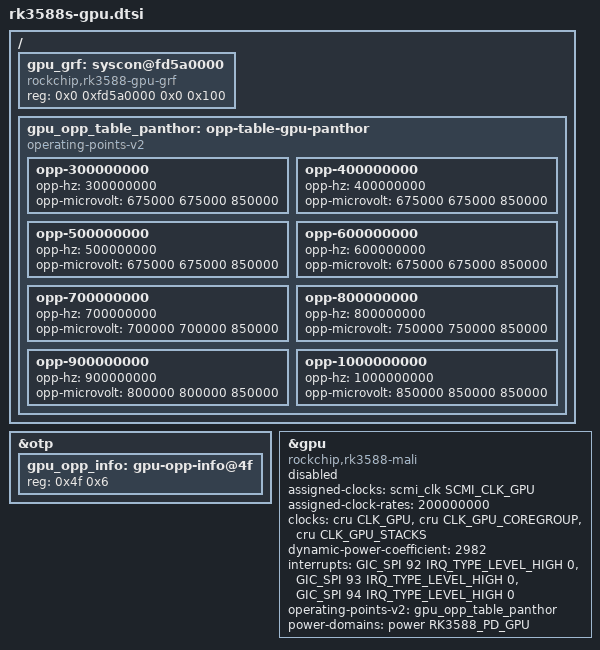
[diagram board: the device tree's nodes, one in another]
/*
 * Copyright (c) 2021 Rockchip Electronics Co., Ltd.
 * Copyright (c) 2025 jjm2473 <jjm2473@gmail.com>
 *
 * Fix: keep the upstream gpu node label and only adjust the properties needed
 * for the mainline panthor driver on RK3588 Mali-G610 / Valhall CSF.
 */

&otp {
	gpu_opp_info: gpu-opp-info@4f {
		reg = <0x4f 0x6>;
	};
};
/ {
	gpu_grf: syscon@fd5a0000 {
		compatible = "rockchip,rk3588-gpu-grf", "syscon";
		reg = <0x0 0xfd5a0000 0x0 0x100>;
	};

	gpu_opp_table_panthor: opp-table-gpu-panthor {
		compatible = "operating-points-v2";

		opp-300000000 {
			opp-hz = /bits/ 64 <300000000>;
			opp-microvolt = <675000 675000 850000>;
		};
		opp-400000000 {
			opp-hz = /bits/ 64 <400000000>;
			opp-microvolt = <675000 675000 850000>;
		};
		opp-500000000 {
			opp-hz = /bits/ 64 <500000000>;
			opp-microvolt = <675000 675000 850000>;
		};
		opp-600000000 {
			opp-hz = /bits/ 64 <600000000>;
			opp-microvolt = <675000 675000 850000>;
		};
		opp-700000000 {
			opp-hz = /bits/ 64 <700000000>;
			opp-microvolt = <700000 700000 850000>;
		};
		opp-800000000 {
			opp-hz = /bits/ 64 <800000000>;
			opp-microvolt = <750000 750000 850000>;
		};
		opp-900000000 {
			opp-hz = /bits/ 64 <900000000>;
			opp-microvolt = <800000 800000 850000>;
		};
		opp-1000000000 {
			opp-hz = /bits/ 64 <1000000000>;
			opp-microvolt = <850000 850000 850000>;
		};
	};
};

/* 修改原有的 gpu 节点以使用 Valhall 架构驱动 */
&gpu {
	compatible = "rockchip,rk3588-mali", "arm,mali-valhall-csf";
	#cooling-cells = <2>;
	assigned-clocks = <&scmi_clk SCMI_CLK_GPU>;
	assigned-clock-rates = <200000000>;
	clocks = <&cru CLK_GPU>, <&cru CLK_GPU_COREGROUP>,
		 <&cru CLK_GPU_STACKS>;
	clock-names = "core", "coregroup", "stacks";
	dynamic-power-coefficient = <2982>;
	interrupts = <GIC_SPI 92 IRQ_TYPE_LEVEL_HIGH 0>,
		     <GIC_SPI 93 IRQ_TYPE_LEVEL_HIGH 0>,
		     <GIC_SPI 94 IRQ_TYPE_LEVEL_HIGH 0>;
	interrupt-names = "job", "mmu", "gpu";
	operating-points-v2 = <&gpu_opp_table_panthor>;
	power-domains = <&power RK3588_PD_GPU>;
	status = "disabled";
};
